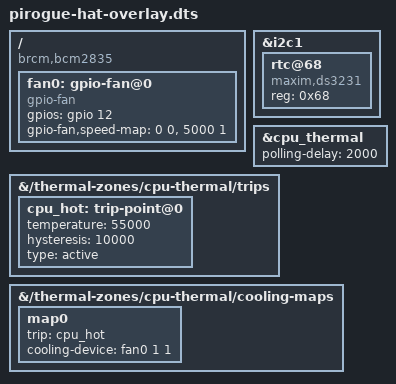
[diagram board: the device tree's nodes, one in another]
/dts-v1/;
/plugin/;

/ {
	compatible = "brcm,bcm2835";

/* Usual I2C/RTC integration. */

	fragment@0 {
		target = <&i2c1>;
		__overlay__ {
			rtc@68 {
				compatible = "maxim,ds3231";
				reg = <0x68>;
			};
		};
	};


/* Adapted from gpio-fan-overlay.dts found in the rpi-6.1.y branch.
 *
 * Changes:
 *  - fragments renumbered to account for the first fragment (I2C/RTC);
 *  - minor rewrapping;
 *  - target = <&thermal_trips> replaced with a target-path (no such label);
 *  - target = <&cooling_maps> replaced with a target-path (no such label).
 */

	fragment@1 {
		target-path = "/";
		__overlay__ {
			fan0: gpio-fan@0 {
				compatible = "gpio-fan";
				gpios = <&gpio 12 0>;
				gpio-fan,speed-map = <0 0>, <5000 1>;
				#cooling-cells = <2>;
			};
		};
	};

	fragment@2 {
		target = <&cpu_thermal>;
		__overlay__ {
			polling-delay = <2000>;	/* milliseconds */
		};
	};

	fragment@3 {
		target-path = "/thermal-zones/cpu-thermal/trips";
		__overlay__ {
			cpu_hot: trip-point@0 {
				temperature = <55000>;	/* (millicelsius) Fan started at 55°C */
				hysteresis = <10000>;	/* (millicelsius) Fan stopped at 45°C */
				type = "active";
			};
		};
	};

	fragment@4 {
		target-path = "/thermal-zones/cpu-thermal/cooling-maps";
		__overlay__ {
			map0 {
				trip = <&cpu_hot>;
				cooling-device = <&fan0 1 1>;
			};
		};
	};

	__overrides__ {
		gpiopin = <&fan0>,"gpios:4", <&fan0>,"brcm,pins:0";
		temp = <&cpu_hot>,"temperature:0";
		hyst = <&cpu_hot>,"hysteresis:0";
	};
};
